# CH564 register map
Vendor: WCH Ltd.; File version: 1.0
Registers are 8-bit, read-write, reset 0x0 unless marked. A register's access mark holds for its fields unless they carry their own. Offsets are from the block's base; [hi:lo] are bit positions.

## TIMER1 — TMR1 register
Base 0x40408400
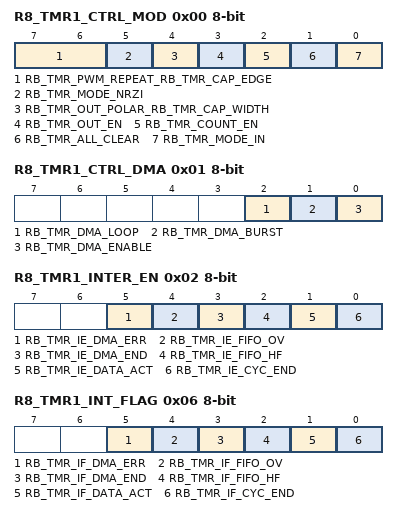
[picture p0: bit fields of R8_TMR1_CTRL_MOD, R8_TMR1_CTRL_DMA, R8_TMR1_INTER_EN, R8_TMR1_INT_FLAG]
0x00 R8_TMR1_CTRL_MOD — TMR1 mode control
  [7:6] RB_TMR_PWM_REPEAT_RB_TMR_CAP_EDGE — timer PWM repeat mode / timer capture edge mode
  [5] RB_TMR_MODE_NRZI — timer serial codec mode
  [4] RB_TMR_OUT_POLAR_RB_TMR_CAP_WIDTH — timer PWM output polarity / Capture pulse width
  [3] RB_TMR_OUT_EN — timer output enable
  [2] RB_TMR_COUNT_EN — timer count enable
  [1] RB_TMR_ALL_CLEAR — force clear timer FIFO and count
  [0] RB_TMR_MODE_IN — timer in mode
0x01 R8_TMR1_CTRL_DMA — TMR1 DMA control register
  [2] RB_TMR_DMA_LOOP — DMA address round-robin mode enabled
  [1] RB_TMR_DMA_BURST — DMA burst operation
  [0] RB_TMR_DMA_ENABLE — DMA function enable
0x02 R8_TMR1_INTER_EN — TMR1 interrupt enable
  [5] RB_TMR_IE_DMA_ERR — enable DMA error responde interrupt
  [4] RB_TMR_IE_FIFO_OV — enable interrupt for timer FIFO overflow
  [3] RB_TMR_IE_DMA_END — enable interrupt for timer DMA completion
  [2] RB_TMR_IE_FIFO_HF — enable interrupt for timer FIFO half (capture fifo >=4 or PWM fifo lower than3)
  [1] RB_TMR_IE_DATA_ACT — enable interrupt for timer capture input action or PWM trigger
  [0] RB_TMR_IE_CYC_END — enable interrupt for timer capture count timeout or PWM cycle end
0x06 R8_TMR1_INT_FLAG — TMR1 interrupt flag
  [5] RB_TMR_IF_DMA_ERR — DMA error responde flag
  [4] RB_TMR_IF_FIFO_OV — interrupt flag for timer FIFO overflow
  [3] RB_TMR_IF_DMA_END — interrupt flag for timer DMA completion
  [2] RB_TMR_IF_FIFO_HF — interrupt flag for timer FIFO half
  [1] RB_TMR_IF_DATA_ACT — interrupt flag for timer capture input action or PWM trigger
  [0] RB_TMR_IF_CYC_END — interrupt flag for timer capture count timeout or PWM cycle end
0x07 R8_TMR1_FIFO_COUNT ro — TMR1 FIFO count status
  [7:0] TMR1_FIFO_COUNT
0x08 R32_TMR1_COUNT 32-bit ro — TMR1 current count
  [27:0] TMR1_COUNT
0x0C R32_TMR1_CNT_END 32-bit — TMR1 end count value, only low 28 bit
  [27:0] TMR1_CNT_END — The number of timer ticks in timer mode
0x10 R32_TMR1_FIFO 32-bit read-only/write-only — TMR1 FIFO register, only low 28 bit
  [27:0] TMR1_FIFO — TMR1 FIFO current count
0x14 R32_TMR1_DMA_NOW 32-bit ro — DMA current buffer address register
  [17:0] TMR1_DMA_NOW — DMA current buffer address
0x18 R32_TMR1_DMA_BEG 32-bit — DMA start buffer address register
  [17:0] TMR1_DMA_BEG — DMA start buffer address
0x1C R32_TMR1_DMA_END 32-bit — DMA end buffer address register
  [17:0] TMR1_DMA_END — DMA end buffer address

## TIMER2 — TMR2 register
Base 0x40408800
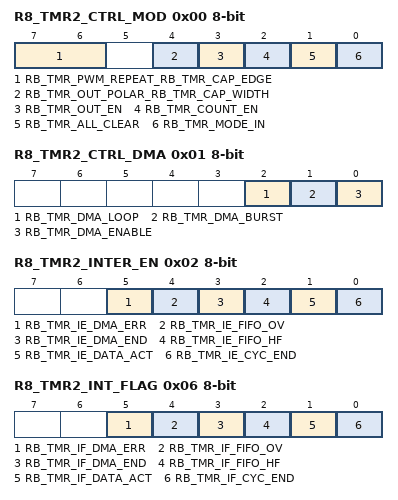
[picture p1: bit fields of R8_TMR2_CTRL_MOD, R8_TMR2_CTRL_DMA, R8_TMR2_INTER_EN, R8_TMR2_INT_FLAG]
0x00 R8_TMR2_CTRL_MOD — TMR2 mode control
  [7:6] RB_TMR_PWM_REPEAT_RB_TMR_CAP_EDGE — timer PWM repeat mode / timer capture edge mode
  [4] RB_TMR_OUT_POLAR_RB_TMR_CAP_WIDTH — timer PWM output polarity / Capture pulse width
  [3] RB_TMR_OUT_EN — timer output enable
  [2] RB_TMR_COUNT_EN — timer count enable
  [1] RB_TMR_ALL_CLEAR — force clear timer FIFO and count
  [0] RB_TMR_MODE_IN — timer in mode
0x01 R8_TMR2_CTRL_DMA — TMR2 DMA control register
  [2] RB_TMR_DMA_LOOP — DMA address round-robin mode enabled
  [1] RB_TMR_DMA_BURST — DMA burst operation
  [0] RB_TMR_DMA_ENABLE — DMA function enable
0x02 R8_TMR2_INTER_EN — TMR2 interrupt enable
  [5] RB_TMR_IE_DMA_ERR — enable DMA error responde interrupt
  [4] RB_TMR_IE_FIFO_OV — enable interrupt for timer FIFO overflow
  [3] RB_TMR_IE_DMA_END — enable interrupt for timer DMA completion
  [2] RB_TMR_IE_FIFO_HF — enable interrupt for timer FIFO half (capture fifo >=4 or PWM fifo lower than3)
  [1] RB_TMR_IE_DATA_ACT — enable interrupt for timer capture input action or PWM trigger
  [0] RB_TMR_IE_CYC_END — enable interrupt for timer capture count timeout or PWM cycle end
0x06 R8_TMR2_INT_FLAG — TMR2 interrupt flag
  [5] RB_TMR_IF_DMA_ERR — DMA error responde flag
  [4] RB_TMR_IF_FIFO_OV — interrupt flag for timer FIFO overflow
  [3] RB_TMR_IF_DMA_END — interrupt flag for timer DMA completion
  [2] RB_TMR_IF_FIFO_HF — interrupt flag for timer FIFO half
  [1] RB_TMR_IF_DATA_ACT — interrupt flag for timer capture input action or PWM trigger
  [0] RB_TMR_IF_CYC_END — interrupt flag for timer capture count timeout or PWM cycle end
0x07 R8_TMR2_FIFO_COUNT ro — TMR2 FIFO count status
  [7:0] TMR2_FIFO_COUNT
0x08 R32_TMR2_COUNT 32-bit ro — TMR2 current count
  [27:0] TMR2_COUNT
0x0C R32_TMR2_CNT_END 32-bit — TMR2 end count value, only low 28 bit
  [27:0] TMR2_CNT_END — The number of timer ticks in timer mode
0x10 R32_TMR2_FIFO 32-bit read-only/write-only — TMR2 FIFO register, only low 28 bit
  [27:0] TMR2_FIFO — TMR2 FIFO current count
0x14 R32_TMR2_DMA_NOW 32-bit ro — DMA current buffer address register
  [17:0] TMR2_DMA_NOW — DMA current buffer address
0x18 R32_TMR2_DMA_BEG 32-bit — DMA start buffer address register
  [17:0] TMR2_DMA_BEG — DMA start buffer address
0x1C R32_TMR2_DMA_END 32-bit — DMA end buffer address register
  [17:0] TMR2_DMA_END — DMA end buffer address
